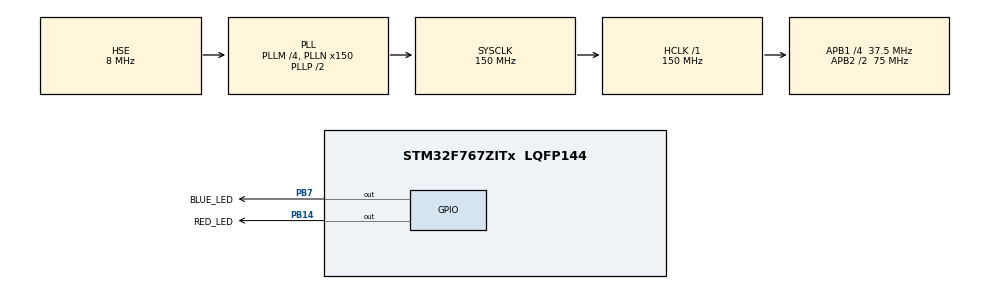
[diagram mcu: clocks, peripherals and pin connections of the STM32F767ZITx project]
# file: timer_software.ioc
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Mcu.Family=STM32F7
Mcu.Name=STM32F767ZITx
Mcu.Package=LQFP144
NVIC.PriorityGroup=NVIC_PRIORITYGROUP_4
NVIC.TIM8_TRG_COM_TIM14_IRQn=true\:0\:0\:false\:false\:true\:true\:true\:true
PB14.GPIO_Label=RED_LED
PB14.Signal=GPIO_Output
PB7.GPIO_Label=BLUE_LED
PB7.Signal=GPIO_Output
PH0/OSC_IN.Mode=HSE-External-Oscillator
PH0/OSC_IN.Signal=RCC_OSC_IN
PH1/OSC_OUT.Mode=HSE-External-Oscillator
PH1/OSC_OUT.Signal=RCC_OSC_OUT
ProjectManager.HeapSize=0x200
ProjectManager.StackSize=0x400
ProjectManager.TargetToolchain=STM32CubeIDE
RCC.AHBFreq_Value=150000000
RCC.APB1CLKDivider=RCC_HCLK_DIV4
RCC.APB1Freq_Value=37500000
RCC.APB1TimFreq_Value=75000000
RCC.APB2CLKDivider=RCC_HCLK_DIV2
RCC.APB2Freq_Value=75000000
RCC.APB2TimFreq_Value=150000000
RCC.CortexFreq_Value=150000000
RCC.HCLKFreq_Value=150000000
RCC.HSE_VALUE=8000000
RCC.HSI_VALUE=16000000
RCC.LSE_VALUE=32768
RCC.PLLM=4
RCC.PLLN=150
RCC.PLLSourceVirtual=RCC_PLLSOURCE_HSE
RCC.SYSCLKFreq_VALUE=150000000
RCC.SYSCLKSource=RCC_SYSCLKSOURCE_PLLCLK
RCC.USBFreq_Value=150000000
RCC.VCOOutputFreq_Value=300000000
TIM14.Prescaler=74
VP_TIM14_VS_ClockSourceINT.Mode=Enable_Timer
board=custom

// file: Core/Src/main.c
/* USER CODE BEGIN Header */
/**
  ******************************************************************************
  * @file           : main.c
  * @brief          : Main program body
  ******************************************************************************
  * @attention
  *
  * Copyright (c) 2026 STMicroelectronics.
  * All rights reserved.
  *
  * This software is licensed under terms that can be found in the LICENSE file
  * in the root directory of this software component.
  * If no LICENSE file comes with this software, it is provided AS-IS.
  *
  ******************************************************************************
  */
/* USER CODE END Header */
#include "main.h"

/* USER CODE BEGIN Includes */
#include "software_timer.h"
/* USER CODE END Includes */

TIM_HandleTypeDef htim14;

/* USER CODE BEGIN PV */
Stimer_t sTime_1s;
Stimer_t sTime_halfs;
/* USER CODE END PV */

void SystemClock_Config(void);
static void MX_GPIO_Init(void);
static void MX_TIM14_Init(void);

int main(void)
{

  /* MCU Configuration--------------------------------------------------------*/

  /* Reset of all peripherals, Initializes the Flash interface and the Systick. */
  HAL_Init();

  /* Configure the system clock */
  SystemClock_Config();

  /* Initialize all configured peripherals */
  MX_GPIO_Init();
  MX_TIM14_Init();
  /* USER CODE BEGIN 2 */
  software_timer_Init(&htim14);
  software_set_time(&sTime_1s, 1000);
  software_set_time(&sTime_halfs, 500);
  /* USER CODE END 2 */

  /* Infinite loop */
  while (1)
  {

    /* USER CODE BEGIN 3 */

	  if(software_timer_check_elapsed_time(&sTime_1s))
	  {
		  HAL_GPIO_TogglePin(BLUE_LED_GPIO_Port, BLUE_LED_Pin);
		  software_set_time(&sTime_1s, 1000);
	  }

	  if(software_timer_check_elapsed_time(&sTime_halfs))
	  {
		  HAL_GPIO_TogglePin(RED_LED_GPIO_Port, RED_LED_Pin);
		  software_set_time(&sTime_halfs, 500);
	  }

  }
  /* USER CODE END 3 */
}

void SystemClock_Config(void)
{
  RCC_OscInitTypeDef RCC_OscInitStruct = {0};
  RCC_ClkInitTypeDef RCC_ClkInitStruct = {0};

  /** Configure the main internal regulator output voltage
  */
  __HAL_RCC_PWR_CLK_ENABLE();
  __HAL_PWR_VOLTAGESCALING_CONFIG(PWR_REGULATOR_VOLTAGE_SCALE2);

  /** Initializes the RCC Oscillators according to the specified parameters
  * in the RCC_OscInitTypeDef structure.
  */
  RCC_OscInitStruct.OscillatorType = RCC_OSCILLATORTYPE_HSE;
  RCC_OscInitStruct.HSEState = RCC_HSE_ON;
  RCC_OscInitStruct.PLL.PLLState = RCC_PLL_ON;
  RCC_OscInitStruct.PLL.PLLSource = RCC_PLLSOURCE_HSE;
  RCC_OscInitStruct.PLL.PLLM = 4;
  RCC_OscInitStruct.PLL.PLLN = 150;
  RCC_OscInitStruct.PLL.PLLP = RCC_PLLP_DIV2;
  RCC_OscInitStruct.PLL.PLLQ = 2;
  RCC_OscInitStruct.PLL.PLLR = 2;
  if (HAL_RCC_OscConfig(&RCC_OscInitStruct) != HAL_OK)
  {
    Error_Handler();
  }

  /** Initializes the CPU, AHB and APB buses clocks
  */
  RCC_ClkInitStruct.ClockType = RCC_CLOCKTYPE_HCLK|RCC_CLOCKTYPE_SYSCLK
                              |RCC_CLOCKTYPE_PCLK1|RCC_CLOCKTYPE_PCLK2;
  RCC_ClkInitStruct.SYSCLKSource = RCC_SYSCLKSOURCE_PLLCLK;
  RCC_ClkInitStruct.AHBCLKDivider = RCC_SYSCLK_DIV1;
  RCC_ClkInitStruct.APB1CLKDivider = RCC_HCLK_DIV4;
  RCC_ClkInitStruct.APB2CLKDivider = RCC_HCLK_DIV2;

  if (HAL_RCC_ClockConfig(&RCC_ClkInitStruct, FLASH_LATENCY_4) != HAL_OK)
  {
    Error_Handler();
  }
}

static void MX_TIM14_Init(void)
{

  htim14.Instance = TIM14;
  htim14.Init.Prescaler = 74;
  htim14.Init.CounterMode = TIM_COUNTERMODE_UP;
  htim14.Init.Period = 999;
  htim14.Init.ClockDivision = TIM_CLOCKDIVISION_DIV1;
  htim14.Init.AutoReloadPreload = TIM_AUTORELOAD_PRELOAD_DISABLE;
  if (HAL_TIM_Base_Init(&htim14) != HAL_OK)
  {
    Error_Handler();
  }

}

static void MX_GPIO_Init(void)
{
  GPIO_InitTypeDef GPIO_InitStruct = {0};

  /* GPIO Ports Clock Enable */
  __HAL_RCC_GPIOH_CLK_ENABLE();
  __HAL_RCC_GPIOB_CLK_ENABLE();

  /*Configure GPIO pin Output Level */
  HAL_GPIO_WritePin(GPIOB, RED_LED_Pin|BLUE_LED_Pin, GPIO_PIN_RESET);

  /*Configure GPIO pins : RED_LED_Pin BLUE_LED_Pin */
  GPIO_InitStruct.Pin = RED_LED_Pin|BLUE_LED_Pin;
  GPIO_InitStruct.Mode = GPIO_MODE_OUTPUT_PP;
  GPIO_InitStruct.Pull = GPIO_NOPULL;
  GPIO_InitStruct.Speed = GPIO_SPEED_FREQ_LOW;
  HAL_GPIO_Init(GPIOB, &GPIO_InitStruct);

}

void Error_Handler(void)
{
  __disable_irq();
  while (1)
  {
  }
}
